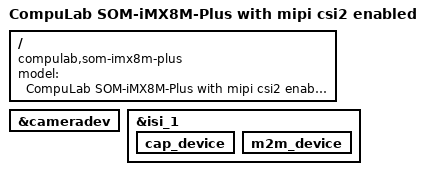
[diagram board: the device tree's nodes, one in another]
// SPDX-License-Identifier: (GPL-2.0+ OR MIT)
/*
 * Copyright 2021 CompuLab
 */

/dts-v1/;

#include "som-imx8m-plus.dts"
#include "som-imx8m-plus_mipi-csi2.dtsi"

/ {
	model = "CompuLab SOM-iMX8M-Plus with mipi csi2 enabled";
	compatible = "compulab,som-imx8m-plus", "fsl,imx8mp";
};

&cameradev {
	status = "okay";
};

&isi_1 {
	status = "okay";

	cap_device {
		status = "okay";
	};

	m2m_device {
		status = "okay";
	};
};
